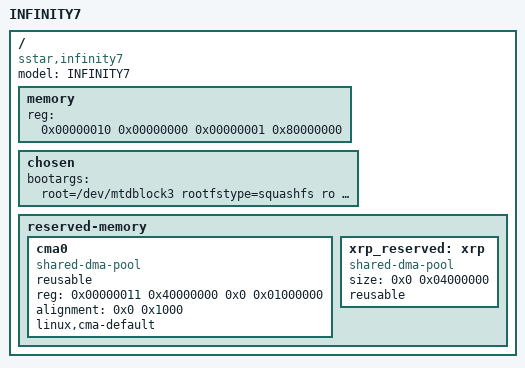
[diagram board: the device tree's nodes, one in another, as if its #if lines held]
/*
* infinity7_aarch64_fpga_flash.dts- Sigmastar
*
* Copyright (c) [2019~2020] SigmaStar Technology.
*
*
* This software is licensed under the terms of the GNU General Public
* License version 2, as published by the Free Software Foundation, and
* may be copied, distributed, and modified under those terms.
*
* This program is distributed in the hope that it will be useful,
* but WITHOUT ANY WARRANTY; without even the implied warranty of
* MERCHANTABILITY or FITNESS FOR A PARTICULAR PURPOSE.  See the
* GNU General Public License version 2 for more details.
*
*/


/dts-v1/;
/*
 * This is used for runing on simulation, but put the kernel and system
 * into the flash storage.
 */
#include "infinity7_aarch64_fpga.dtsi"

/ {
    model = "INFINITY7";
    compatible = "sstar,infinity7";
    #address-cells = <2>;
    #size-cells = <2>;

    memory {
        device_type = "memory";
        #address-cells = <2>;
        #size-cells = <2>;
        reg = <0x00000010 0x00000000 0x00000001 0x80000000>;
    };

#ifdef CONFIG_SS_NOR_ONEBIN
    chosen {
        bootargs = "root=/dev/mtdblock3 rootfstype=squashfs ro init=/linuxrc LX_MEM=0x1000000000,0x180000000 mma_heap=mma_heap_name0,miu=0,sz=0x6000000,max_start_off=0x1100000000,max_end_off=0x1106000000, mtdparts=nor0:0x4F000(BOOT),0x1000(ENV),0x780000(KERNEL),0x380000(system),0x4B0000(data), nohz=off";
    };
#elif CONFIG_SS_NAND_ONEBIN
    chosen {
        bootargs = "ubi.mtd=UBI,2048 root=/dev/mtdblock5 rootfstype=squashfs ro init=/linuxrc LX_MEM=0xffe0000 mma_heap=mma_heap_name0,miu=0,sz=0x9E9C000 mma_heap=mma_heap_ipu,miu=0,sz=0x164000 mma_memblock_remove=1 cma=2M mtdparts=nand0:1536k@1280k(BOOT0),1536k(BOOT1),384k(ENV),8m(KERNEL),8m(RECOVERY),6m(rootfs),384k(MISC),101m(UBI), nohz=off";
    };
#endif

    /*!!IMPORTANT!! The reserved memory must be 1MB aligned*/
    reserved-memory {
        #address-cells = <2>;
        #size-cells = <2>;
        ranges;

        cma0 {
            compatible = "shared-dma-pool";
            reusable;
            reg = <0x00000011 0x40000000 0x0 0x01000000>;
            alignment = <0x0 0x1000>;
            linux,cma-default;
        };
        xrp_reserved: xrp {
            compatible = "shared-dma-pool";
            size = <0x0 0x04000000>;
            reusable;
        };
    };

};
